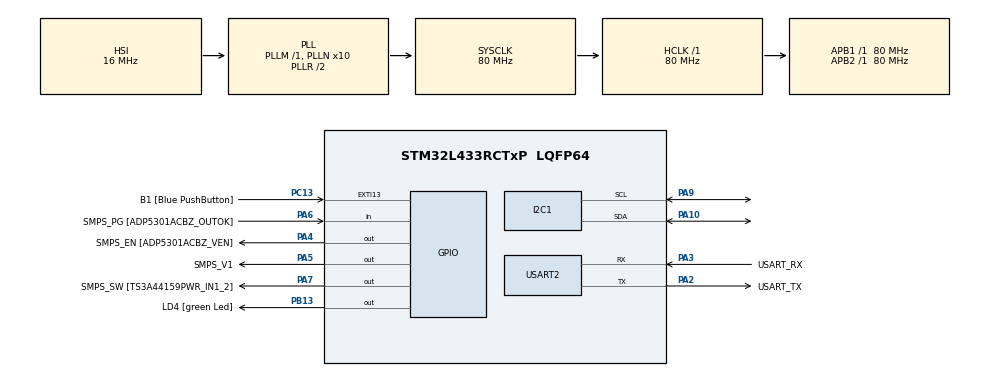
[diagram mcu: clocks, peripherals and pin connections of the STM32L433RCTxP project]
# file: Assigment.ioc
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I2C1.Timing=0x10909CEC
Mcu.Family=STM32L4
Mcu.Name=STM32L433RCTxP
Mcu.Package=LQFP64
NVIC.PriorityGroup=NVIC_PRIORITYGROUP_4
PA10.Mode=I2C
PA10.Signal=I2C1_SDA
PA13\ (JTMS-SWDIO).GPIO_Label=TMS
PA13\ (JTMS-SWDIO).Mode=Serial_Wire
PA13\ (JTMS-SWDIO).Signal=SYS_JTMS-SWDIO
PA14\ (JTCK-SWCLK).GPIO_Label=TCK
PA14\ (JTCK-SWCLK).Mode=Serial_Wire
PA14\ (JTCK-SWCLK).Signal=SYS_JTCK-SWCLK
PA2.GPIO_Label=USART_TX
PA2.GPIO_Mode=GPIO_MODE_AF_PP
PA2.GPIO_PuPd=GPIO_NOPULL
PA2.GPIO_Speed=GPIO_SPEED_FREQ_VERY_HIGH
PA2.Mode=Asynchronous
PA2.Signal=USART2_TX
PA3.GPIO_Label=USART_RX
PA3.GPIO_Mode=GPIO_MODE_AF_PP
PA3.GPIO_PuPd=GPIO_NOPULL
PA3.GPIO_Speed=GPIO_SPEED_FREQ_VERY_HIGH
PA3.Mode=Asynchronous
PA3.Signal=USART2_RX
PA4.GPIO_Label=SMPS_EN [ADP5301ACBZ_VEN]
PA4.Signal=GPIO_Output
PA5.GPIO_Label=SMPS_V1
PA5.GPIO_ModeDefaultOutputPP=GPIO_MODE_OUTPUT_PP
PA5.GPIO_PuPd=GPIO_NOPULL
PA5.GPIO_Speed=GPIO_SPEED_FREQ_LOW
PA5.Signal=GPIO_Output
PA6.GPIO_Label=SMPS_PG [ADP5301ACBZ_OUTOK]
PA6.GPIO_PuPd=GPIO_PULLUP
PA6.Signal=GPIO_Input
PA7.GPIO_Label=SMPS_SW [TS3A44159PWR_IN1_2]
PA7.Signal=GPIO_Output
PA9.Mode=I2C
PA9.Signal=I2C1_SCL
PB13.GPIO_Label=LD4 [green Led]
PB13.Signal=GPIO_Output
PB3\ (JTDO-TRACESWO).GPIO_Label=SWO
PB3\ (JTDO-TRACESWO).Signal=SYS_JTDO-SWO
PC13.GPIO_Label=B1 [Blue PushButton]
PC13.GPIO_ModeDefaultEXTI=GPIO_MODE_IT_FALLING
PC13.GPIO_PuPd=GPIO_NOPULL
PC13.Signal=GPXTI13
PC14-OSC32_IN\ (PC14).Mode=LSE-External-Oscillator
PC14-OSC32_IN\ (PC14).Signal=RCC_OSC32_IN
PC15-OSC32_OUT\ (PC15).Mode=LSE-External-Oscillator
PC15-OSC32_OUT\ (PC15).Signal=RCC_OSC32_OUT
PH0-OSC_IN\ (PH0).GPIO_Label=MCO
PH0-OSC_IN\ (PH0).Mode=HSE-External-Clock-Source
PH0-OSC_IN\ (PH0).Signal=RCC_OSC_IN
PH1-OSC_OUT\ (PH1).Signal=RCC_OSC_OUT
ProjectManager.HeapSize=0x200
ProjectManager.StackSize=0x400
ProjectManager.TargetToolchain=STM32CubeIDE
RCC.ADCFreq_Value=64000000
RCC.AHBFreq_Value=80000000
RCC.APB1Freq_Value=80000000
RCC.APB1TimFreq_Value=80000000
RCC.APB2Freq_Value=80000000
RCC.APB2TimFreq_Value=80000000
RCC.CortexFreq_Value=80000000
RCC.HCLKFreq_Value=80000000
RCC.HSE_VALUE=8000000
RCC.HSI48_VALUE=48000000
RCC.HSI_VALUE=16000000
RCC.MSI_VALUE=4000000
RCC.PLLN=10
RCC.PLLSourceVirtual=RCC_PLLSOURCE_HSI
RCC.PREFETCH_ENABLE=1
RCC.SYSCLKFreq_VALUE=80000000
RCC.SYSCLKSource=RCC_SYSCLKSOURCE_PLLCLK
RCC.USBFreq_Value=64000000
RCC.VCOOutputFreq_Value=160000000
USART2.VirtualMode-Asynchronous=VM_ASYNC
board=NUCLEO-L433RC-P

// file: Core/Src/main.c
/* USER CODE BEGIN Header */
/**
  **************************
  * @file           : main.c
  * @brief          : Main program body
  **************************
  * @attention
  *
  * Copyright (c) 2023 STMicroelectronics.
  * All rights reserved.
  *
  * This software is licensed under terms that can be found in the LICENSE file
  * in the root directory of this software component.
  * If no LICENSE file comes with this software, it is provided AS-IS.
  *
  **************************
  */
/* USER CODE END Header */
#include "main.h"
#include <stdio.h>
#include <string.h>
#include "NanoEdgeAI.h"
#include "knowledge.h"

I2C_HandleTypeDef hi2c1;

UART_HandleTypeDef huart2;

void SystemClock_Config(void);
static void MX_GPIO_Init(void);
static void MX_USART2_UART_Init(void);
static void MX_I2C1_Init(void);
void fill_accelerometer_buffer(void);
void fill_buffer(float);

/* USER CODE BEGIN 0 */
	uint8_t buf [32];
	uint8_t Xaxis[32];
	int16_t x = 1;
	int16_t y = 2;
	int16_t z = 3;
/* USER CODE END 0 */

	#define LIS3DH_G_CHIP_ADDR (0x18 << 1) //SA0 (=SD0 pin ) = Ground
	#define LIS3DH_V_CHIP_ADDR (0x19 << 1) //SA0 (=SD0 pin ) = Vdd

	#define LIS3DH_STATUS_REG_AUX	0x07
	#define LIS3DH_WHO_I_AM		0x0f
	#define LIS3DH_CTRL_REG1	0x20
	#define LIS3DH_CTRL_REG2	0x21
	#define LIS3DH_CTRL_REG3	0x22
	#define LIS3DH_CTRL_REG4	0x23
	#define LIS3DH_CTRL_REG5	0x24
	#define LIS3DH_CTRL_REG6	0x25
	#define LIS3DH_OUT_X_L		0xA8
	#define LIS3DH_OUT_Y_L		0xA9
	#define LIS3DH_OUT_Z_L		0xAA
	#define LIS3DH_DR_LP_1R6KHZ
	#define LIS3DH_FS_4G
	#define BUFFER_SIZE     256
	#define NB_AXES         3

	uint16_t id_class = 0; // Point to id class (see argument of neai_classification fct)
	float input_user_buffer[DATA_INPUT_USER * AXIS_NUMBER]; // Buffer of input values
	float output_class_buffer[CLASS_NUMBER]; // Buffer of class probabilities
	const char *id2class[CLASS_NUMBER + 1] = { // Buffer for mapping class id to class name
		"unknown",
		"MIxer_Off",
		"Mixer_On",
	};

int main(void)
{

  /* MCU Configuration--------------------------------------------------------*/

  /* Reset of all peripherals, Initializes the Flash interface and the Systick. */
  HAL_Init();

  /* Configure the system clock */
  SystemClock_Config();

  /* Initialize all configured peripherals */
  MX_GPIO_Init();
  MX_USART2_UART_Init();
  MX_I2C1_Init();
  enum neai_state error_code = neai_classification_init(knowledge);
    	if (error_code != NEAI_OK) {
    		printf("ERROR: Accelerometer not found");
    	}

  /* Infinite loop */

  HAL_StatusTypeDef ret;

  #define LIS3DH_G_CHIP_ADDR (0x18 << 1)
  #define LIS3DH_V_CHIP_ADDR (0x19 << 1)
//

  int16_t x, y, z;
  uint16_t id_class = 0;
  uint8_t reg, data[32];
  uint8_t buf[32];

  	  buf [0] = LIS3DH_CTRL_REG1;
	  buf [1] = 0x97;
	  ret = HAL_I2C_Master_Transmit(&hi2c1,LIS3DH_V_CHIP_ADDR,buf,2 , HAL_MAX_DELAY);

	  if (ret != HAL_OK){

	 		  sprintf ((char*)buf , "ErrorTx WHO_AM_I");
	 		  HAL_UART_Transmit(&huart2 ,buf,strlen((char*)buf), HAL_MAX_DELAY);
	 	  }

	  buf [0] = LIS3DH_CTRL_REG4;
	  buf [1] = 0x08;
	  ret = HAL_I2C_Master_Transmit(&hi2c1,LIS3DH_V_CHIP_ADDR,buf,2 , HAL_MAX_DELAY);

	  if (ret != HAL_OK){

	 		  sprintf ((char*)buf , "ErrorTx WHO_AM_I");
	 		  HAL_UART_Transmit(&huart2 ,buf,strlen((char*)buf), HAL_MAX_DELAY);
	 	  }

  /* USER CODE BEGIN WHILE */
  while(1)
  {
	  buf[0] = LIS3DH_OUT_X_L;

	  ret = HAL_I2C_Master_Transmit(&hi2c1,LIS3DH_V_CHIP_ADDR,buf,1 , HAL_MAX_DELAY);

	  ret =HAL_I2C_Master_Receive(&hi2c1,LIS3DH_V_CHIP_ADDR,buf,6 , HAL_MAX_DELAY);

	  x= buf[1] << 8 | buf[0];
	  y= buf[3] << 8 | buf[2];
	  z= buf[5] << 8 | buf[4];

	  // Print x, y, and z acceleration data to UART console
	  sprintf(buf, "%d %d %d\n", x, y, z);

	  HAL_Delay(50);

//	  neai_classification(input_user_buffer, output_class_buffer, &id_class);
//    /* USER CODE BEGIN 3 */
//	  uint8_t id_class = output_class_buffer[id_class]; // run inference and get similarity score
//	  		if (id_class = 1) { // make decision based on similarity score
//	  			sprintf(buf,"(classification = %s%%)\n", id2class[id_class]);
//	  		} else if (id_class = 2) {
//	  			sprintf(buf,"(classification = %s%%)\n", id2class[id_class]);
//
//			}
	  		HAL_UART_Transmit(&huart2, (uint8_t*)buf, strlen(buf), HAL_MAX_DELAY);
  }
  /* USER CODE END 3 */
}

void SystemClock_Config(void)
{
  RCC_OscInitTypeDef RCC_OscInitStruct = {0};
  RCC_ClkInitTypeDef RCC_ClkInitStruct = {0};

  /** Configure the main internal regulator output voltage
  */
  if (HAL_PWREx_ControlVoltageScaling(PWR_REGULATOR_VOLTAGE_SCALE1) != HAL_OK)
  {
    Error_Handler();
  }

  /** Initializes the RCC Oscillators according to the specified parameters
  * in the RCC_OscInitTypeDef structure.
  */
  RCC_OscInitStruct.OscillatorType = RCC_OSCILLATORTYPE_HSI;
  RCC_OscInitStruct.HSIState = RCC_HSI_ON;
  RCC_OscInitStruct.HSICalibrationValue = RCC_HSICALIBRATION_DEFAULT;
  RCC_OscInitStruct.PLL.PLLState = RCC_PLL_ON;
  RCC_OscInitStruct.PLL.PLLSource = RCC_PLLSOURCE_HSI;
  RCC_OscInitStruct.PLL.PLLM = 1;
  RCC_OscInitStruct.PLL.PLLN = 10;
  RCC_OscInitStruct.PLL.PLLP = RCC_PLLP_DIV7;
  RCC_OscInitStruct.PLL.PLLQ = RCC_PLLQ_DIV2;
  RCC_OscInitStruct.PLL.PLLR = RCC_PLLR_DIV2;
  if (HAL_RCC_OscConfig(&RCC_OscInitStruct) != HAL_OK)
  {
    Error_Handler();
  }

  /** Initializes the CPU, AHB and APB buses clocks
  */
  RCC_ClkInitStruct.ClockType = RCC_CLOCKTYPE_HCLK|RCC_CLOCKTYPE_SYSCLK
                              |RCC_CLOCKTYPE_PCLK1|RCC_CLOCKTYPE_PCLK2;
  RCC_ClkInitStruct.SYSCLKSource = RCC_SYSCLKSOURCE_PLLCLK;
  RCC_ClkInitStruct.AHBCLKDivider = RCC_SYSCLK_DIV1;
  RCC_ClkInitStruct.APB1CLKDivider = RCC_HCLK_DIV1;
  RCC_ClkInitStruct.APB2CLKDivider = RCC_HCLK_DIV1;

  if (HAL_RCC_ClockConfig(&RCC_ClkInitStruct, FLASH_LATENCY_4) != HAL_OK)
  {
    Error_Handler();
  }
}

static void MX_I2C1_Init(void)
{

  hi2c1.Instance = I2C1;
  hi2c1.Init.Timing = 0x10909CEC;
  hi2c1.Init.OwnAddress1 = 0;
  hi2c1.Init.AddressingMode = I2C_ADDRESSINGMODE_7BIT;
  hi2c1.Init.DualAddressMode = I2C_DUALADDRESS_DISABLE;
  hi2c1.Init.OwnAddress2 = 0;
  hi2c1.Init.OwnAddress2Masks = I2C_OA2_NOMASK;
  hi2c1.Init.GeneralCallMode = I2C_GENERALCALL_DISABLE;
  hi2c1.Init.NoStretchMode = I2C_NOSTRETCH_DISABLE;
  if (HAL_I2C_Init(&hi2c1) != HAL_OK)
  {
    Error_Handler();
  }

  /** Configure Analogue filter
  */
  if (HAL_I2CEx_ConfigAnalogFilter(&hi2c1, I2C_ANALOGFILTER_ENABLE) != HAL_OK)
  {
    Error_Handler();
  }

  /** Configure Digital filter
  */
  if (HAL_I2CEx_ConfigDigitalFilter(&hi2c1, 0) != HAL_OK)
  {
    Error_Handler();
  }

}

static void MX_USART2_UART_Init(void)
{

  huart2.Instance = USART2;
  huart2.Init.BaudRate = 115200;
  huart2.Init.WordLength = UART_WORDLENGTH_8B;
  huart2.Init.StopBits = UART_STOPBITS_1;
  huart2.Init.Parity = UART_PARITY_NONE;
  huart2.Init.Mode = UART_MODE_TX_RX;
  huart2.Init.HwFlowCtl = UART_HWCONTROL_NONE;
  huart2.Init.OverSampling = UART_OVERSAMPLING_16;
  huart2.Init.OneBitSampling = UART_ONE_BIT_SAMPLE_DISABLE;
  huart2.AdvancedInit.AdvFeatureInit = UART_ADVFEATURE_NO_INIT;
  if (HAL_UART_Init(&huart2) != HAL_OK)
  {
    Error_Handler();
  }

}

static void MX_GPIO_Init(void)
{
  GPIO_InitTypeDef GPIO_InitStruct = {0};

  /* GPIO Ports Clock Enable */
  __HAL_RCC_GPIOC_CLK_ENABLE();
  __HAL_RCC_GPIOH_CLK_ENABLE();
  __HAL_RCC_GPIOA_CLK_ENABLE();
  __HAL_RCC_GPIOB_CLK_ENABLE();

  /*Configure GPIO pin Output Level */
  HAL_GPIO_WritePin(GPIOA, SMPS_EN_Pin|SMPS_V1_Pin|SMPS_SW_Pin, GPIO_PIN_RESET);

  /*Configure GPIO pin Output Level */
  HAL_GPIO_WritePin(LD4_GPIO_Port, LD4_Pin, GPIO_PIN_RESET);

  /*Configure GPIO pin : B1_Pin */
  GPIO_InitStruct.Pin = B1_Pin;
  GPIO_InitStruct.Mode = GPIO_MODE_IT_FALLING;
  GPIO_InitStruct.Pull = GPIO_NOPULL;
  HAL_GPIO_Init(B1_GPIO_Port, &GPIO_InitStruct);

  /*Configure GPIO pins : SMPS_EN_Pin SMPS_V1_Pin SMPS_SW_Pin */
  GPIO_InitStruct.Pin = SMPS_EN_Pin|SMPS_V1_Pin|SMPS_SW_Pin;
  GPIO_InitStruct.Mode = GPIO_MODE_OUTPUT_PP;
  GPIO_InitStruct.Pull = GPIO_NOPULL;
  GPIO_InitStruct.Speed = GPIO_SPEED_FREQ_LOW;
  HAL_GPIO_Init(GPIOA, &GPIO_InitStruct);

  /*Configure GPIO pin : SMPS_PG_Pin */
  GPIO_InitStruct.Pin = SMPS_PG_Pin;
  GPIO_InitStruct.Mode = GPIO_MODE_INPUT;
  GPIO_InitStruct.Pull = GPIO_PULLUP;
  HAL_GPIO_Init(SMPS_PG_GPIO_Port, &GPIO_InitStruct);

  /*Configure GPIO pin : LD4_Pin */
  GPIO_InitStruct.Pin = LD4_Pin;
  GPIO_InitStruct.Mode = GPIO_MODE_OUTPUT_PP;
  GPIO_InitStruct.Pull = GPIO_NOPULL;
  GPIO_InitStruct.Speed = GPIO_SPEED_FREQ_LOW;
  HAL_GPIO_Init(LD4_GPIO_Port, &GPIO_InitStruct);

}

void Error_Handler(void)
{
  __disable_irq();
  while (1)
  {
  }
}
